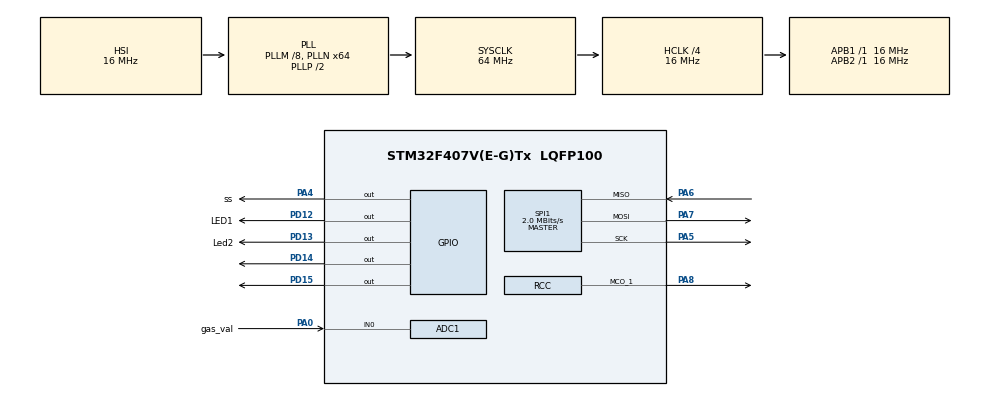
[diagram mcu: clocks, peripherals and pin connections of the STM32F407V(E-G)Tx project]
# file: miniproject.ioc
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ADC1.Channel-2\#ChannelRegularConversion=ADC_CHANNEL_0
ADC1.NbrOfConversionFlag=1
ADC1.Rank-2\#ChannelRegularConversion=1
ADC1.SamplingTime-2\#ChannelRegularConversion=ADC_SAMPLETIME_3CYCLES
ADC1.master=1
Mcu.Family=STM32F4
Mcu.Name=STM32F407V(E-G)Tx
Mcu.Package=LQFP100
NVIC.PriorityGroup=NVIC_PRIORITYGROUP_0
PA0-WKUP.GPIO_Label=gas_val
PA0-WKUP.Signal=ADCx_IN0
PA13.Mode=Serial_Wire
PA13.Signal=SYS_JTMS-SWDIO
PA14.Mode=Serial_Wire
PA14.Signal=SYS_JTCK-SWCLK
PA4.GPIO_Label=ss
PA4.Signal=GPIO_Output
PA5.Mode=Full_Duplex_Master
PA5.Signal=SPI1_SCK
PA6.Mode=Full_Duplex_Master
PA6.Signal=SPI1_MISO
PA7.Mode=Full_Duplex_Master
PA7.Signal=SPI1_MOSI
PA8.Mode=Clock-out-1
PA8.Signal=RCC_MCO_1
PD12.GPIO_Label=LED1
PD12.Signal=GPIO_Output
PD13.GPIO_Label=Led2
PD13.Signal=GPIO_Output
PD14.Signal=GPIO_Output
PD15.Signal=GPIO_Output
PH0-OSC_IN.Mode=HSE-External-Oscillator
PH0-OSC_IN.Signal=RCC_OSC_IN
PH1-OSC_OUT.Mode=HSE-External-Oscillator
PH1-OSC_OUT.Signal=RCC_OSC_OUT
ProjectManager.HeapSize=0x200
ProjectManager.StackSize=0x400
ProjectManager.TargetToolchain=STM32CubeIDE
RCC.48MHZClocksFreq_Value=18285714.285714287
RCC.AHBCLKDivider=RCC_SYSCLK_DIV4
RCC.AHBFreq_Value=16000000
RCC.APB1Freq_Value=16000000
RCC.APB1TimFreq_Value=16000000
RCC.APB2Freq_Value=16000000
RCC.APB2TimFreq_Value=16000000
RCC.CortexFreq_Value=16000000
RCC.HCLKFreq_Value=16000000
RCC.HSE_VALUE=8000000
RCC.HSI_VALUE=16000000
RCC.LSE_VALUE=32768
RCC.PLLM=8
RCC.PLLN=64
RCC.PLLQ=7
RCC.SYSCLKFreq_VALUE=64000000
RCC.SYSCLKSource=RCC_SYSCLKSOURCE_PLLCLK
RCC.VCOOutputFreq_Value=128000000
SH.ADCx_IN0.0=ADC1_IN0,IN0
SPI1.BaudRatePrescaler=SPI_BAUDRATEPRESCALER_8
SPI1.CalculateBaudRate=2.0 MBits/s
SPI1.Direction=SPI_DIRECTION_2LINES
SPI1.Mode=SPI_MODE_MASTER
SPI1.VirtualType=VM_MASTER
board=STM32F407G-DISC1

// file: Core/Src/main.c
/* USER CODE BEGIN Header */
/**
  ******************************************************************************
  * @file           : main.c
  * @brief          : Main program body
  ******************************************************************************
  * @attention
  *
  * <h2><center>&copy; Copyright (c) 2020 STMicroelectronics.
  * All rights reserved.</center></h2>
  *
  * This software component is licensed by ST under Ultimate Liberty license
  * SLA0044, the "License"; You may not use this file except in compliance with
  * the License. You may obtain a copy of the License at:
  *                             www.st.com/SLA0044
  *
  ******************************************************************************
  */
/* USER CODE END Header */
#include "main.h"

ADC_HandleTypeDef hadc1;

SPI_HandleTypeDef hspi1;

void SystemClock_Config(void);
static void MX_GPIO_Init(void);
static void MX_SPI1_Init(void);
static void MX_ADC1_Init(void);

int main(void)
{

  /* MCU Configuration--------------------------------------------------------*/

  /* Reset of all peripherals, Initializes the Flash interface and the Systick. */
  HAL_Init();

  /* Configure the system clock */
  SystemClock_Config();

  /* Initialize all configured peripherals */
  MX_GPIO_Init();
  MX_SPI1_Init();
  MX_ADC1_Init();

  /* Infinite loop */
  /* USER CODE BEGIN WHILE */
HAL_ADC_Start(&hadc1);
uint32_t gas_val;
  while (1)
  {
	  if( HAL_ADC_PollForConversion(&hadc1, 10000) == HAL_OK)
	  {
		  gas_val = HAL_ADC_GetValue(&hadc1);
	  }
	   if(gas_val < 80)
	   {
	   HAL_GPIO_WritePin(GPIOD, GPIO_PIN_12, GPIO_PIN_SET);
	   HAL_Delay(10);
	   HAL_GPIO_WritePin(GPIOD, GPIO_PIN_12, GPIO_PIN_RESET);
	   }
	   else
	   {
	   HAL_GPIO_WritePin(GPIOD, GPIO_PIN_13, GPIO_PIN_SET);
	   HAL_Delay(10);
	   HAL_GPIO_WritePin(GPIOD, GPIO_PIN_13, GPIO_PIN_RESET);
	   }
	   HAL_SPI_Transmit(&hspi1,  &gas_val, 1,10);
    /* USER CODE END WHILE */

  }
}

void SystemClock_Config(void)
{
  RCC_OscInitTypeDef RCC_OscInitStruct = {0};
  RCC_ClkInitTypeDef RCC_ClkInitStruct = {0};

  /** Configure the main internal regulator output voltage
  */
  __HAL_RCC_PWR_CLK_ENABLE();
  __HAL_PWR_VOLTAGESCALING_CONFIG(PWR_REGULATOR_VOLTAGE_SCALE1);
  /** Initializes the RCC Oscillators according to the specified parameters
  * in the RCC_OscInitTypeDef structure.
  */
  RCC_OscInitStruct.OscillatorType = RCC_OSCILLATORTYPE_HSI;
  RCC_OscInitStruct.HSIState = RCC_HSI_ON;
  RCC_OscInitStruct.HSICalibrationValue = RCC_HSICALIBRATION_DEFAULT;
  RCC_OscInitStruct.PLL.PLLState = RCC_PLL_ON;
  RCC_OscInitStruct.PLL.PLLSource = RCC_PLLSOURCE_HSI;
  RCC_OscInitStruct.PLL.PLLM = 8;
  RCC_OscInitStruct.PLL.PLLN = 64;
  RCC_OscInitStruct.PLL.PLLP = RCC_PLLP_DIV2;
  RCC_OscInitStruct.PLL.PLLQ = 7;
  if (HAL_RCC_OscConfig(&RCC_OscInitStruct) != HAL_OK)
  {
    Error_Handler();
  }
  /** Initializes the CPU, AHB and APB buses clocks
  */
  RCC_ClkInitStruct.ClockType = RCC_CLOCKTYPE_HCLK|RCC_CLOCKTYPE_SYSCLK
                              |RCC_CLOCKTYPE_PCLK1|RCC_CLOCKTYPE_PCLK2;
  RCC_ClkInitStruct.SYSCLKSource = RCC_SYSCLKSOURCE_PLLCLK;
  RCC_ClkInitStruct.AHBCLKDivider = RCC_SYSCLK_DIV4;
  RCC_ClkInitStruct.APB1CLKDivider = RCC_HCLK_DIV1;
  RCC_ClkInitStruct.APB2CLKDivider = RCC_HCLK_DIV1;

  if (HAL_RCC_ClockConfig(&RCC_ClkInitStruct, FLASH_LATENCY_0) != HAL_OK)
  {
    Error_Handler();
  }
  HAL_RCC_MCOConfig(RCC_MCO1, RCC_MCO1SOURCE_HSI, RCC_MCODIV_1);
}

static void MX_ADC1_Init(void)
{

  ADC_ChannelConfTypeDef sConfig = {0};

  /** Configure the global features of the ADC (Clock, Resolution, Data Alignment and number of conversion)
  */
  hadc1.Instance = ADC1;
  hadc1.Init.ClockPrescaler = ADC_CLOCK_SYNC_PCLK_DIV2;
  hadc1.Init.Resolution = ADC_RESOLUTION_12B;
  hadc1.Init.ScanConvMode = DISABLE;
  hadc1.Init.ContinuousConvMode = DISABLE;
  hadc1.Init.DiscontinuousConvMode = DISABLE;
  hadc1.Init.ExternalTrigConvEdge = ADC_EXTERNALTRIGCONVEDGE_NONE;
  hadc1.Init.ExternalTrigConv = ADC_SOFTWARE_START;
  hadc1.Init.DataAlign = ADC_DATAALIGN_RIGHT;
  hadc1.Init.NbrOfConversion = 1;
  hadc1.Init.DMAContinuousRequests = DISABLE;
  hadc1.Init.EOCSelection = ADC_EOC_SINGLE_CONV;
  if (HAL_ADC_Init(&hadc1) != HAL_OK)
  {
    Error_Handler();
  }
  /** Configure for the selected ADC regular channel its corresponding rank in the sequencer and its sample time.
  */
  sConfig.Channel = ADC_CHANNEL_0;
  sConfig.Rank = 1;
  sConfig.SamplingTime = ADC_SAMPLETIME_3CYCLES;
  if (HAL_ADC_ConfigChannel(&hadc1, &sConfig) != HAL_OK)
  {
    Error_Handler();
  }

}

static void MX_SPI1_Init(void)
{

  /* SPI1 parameter configuration*/
  hspi1.Instance = SPI1;
  hspi1.Init.Mode = SPI_MODE_MASTER;
  hspi1.Init.Direction = SPI_DIRECTION_2LINES;
  hspi1.Init.DataSize = SPI_DATASIZE_8BIT;
  hspi1.Init.CLKPolarity = SPI_POLARITY_LOW;
  hspi1.Init.CLKPhase = SPI_PHASE_1EDGE;
  hspi1.Init.NSS = SPI_NSS_SOFT;
  hspi1.Init.BaudRatePrescaler = SPI_BAUDRATEPRESCALER_8;
  hspi1.Init.FirstBit = SPI_FIRSTBIT_MSB;
  hspi1.Init.TIMode = SPI_TIMODE_DISABLE;
  hspi1.Init.CRCCalculation = SPI_CRCCALCULATION_DISABLE;
  hspi1.Init.CRCPolynomial = 10;
  if (HAL_SPI_Init(&hspi1) != HAL_OK)
  {
    Error_Handler();
  }

}

static void MX_GPIO_Init(void)
{
  GPIO_InitTypeDef GPIO_InitStruct = {0};

  /* GPIO Ports Clock Enable */
  __HAL_RCC_GPIOH_CLK_ENABLE();
  __HAL_RCC_GPIOA_CLK_ENABLE();
  __HAL_RCC_GPIOD_CLK_ENABLE();

  /*Configure GPIO pin Output Level */
  HAL_GPIO_WritePin(ss_GPIO_Port, ss_Pin, GPIO_PIN_RESET);

  /*Configure GPIO pin Output Level */
  HAL_GPIO_WritePin(GPIOD, LED1_Pin|Led2_Pin|GPIO_PIN_14|GPIO_PIN_15, GPIO_PIN_RESET);

  /*Configure GPIO pin : ss_Pin */
  GPIO_InitStruct.Pin = ss_Pin;
  GPIO_InitStruct.Mode = GPIO_MODE_OUTPUT_PP;
  GPIO_InitStruct.Pull = GPIO_NOPULL;
  GPIO_InitStruct.Speed = GPIO_SPEED_FREQ_LOW;
  HAL_GPIO_Init(ss_GPIO_Port, &GPIO_InitStruct);

  /*Configure GPIO pins : LED1_Pin Led2_Pin PD14 PD15 */
  GPIO_InitStruct.Pin = LED1_Pin|Led2_Pin|GPIO_PIN_14|GPIO_PIN_15;
  GPIO_InitStruct.Mode = GPIO_MODE_OUTPUT_PP;
  GPIO_InitStruct.Pull = GPIO_NOPULL;
  GPIO_InitStruct.Speed = GPIO_SPEED_FREQ_LOW;
  HAL_GPIO_Init(GPIOD, &GPIO_InitStruct);

  /*Configure GPIO pin : PA8 */
  GPIO_InitStruct.Pin = GPIO_PIN_8;
  GPIO_InitStruct.Mode = GPIO_MODE_AF_PP;
  GPIO_InitStruct.Pull = GPIO_NOPULL;
  GPIO_InitStruct.Speed = GPIO_SPEED_FREQ_LOW;
  GPIO_InitStruct.Alternate = GPIO_AF0_MCO;
  HAL_GPIO_Init(GPIOA, &GPIO_InitStruct);

}

void Error_Handler(void)
{
}

/************************ (C) COPYRIGHT STMicroelectronics *****END OF FILE****/
